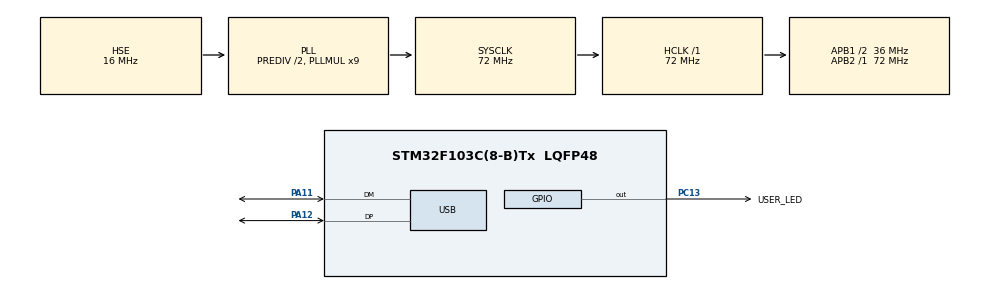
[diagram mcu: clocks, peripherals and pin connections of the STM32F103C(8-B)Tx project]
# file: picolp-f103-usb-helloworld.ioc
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Mcu.Family=STM32F1
Mcu.Name=STM32F103C(8-B)Tx
Mcu.Package=LQFP48
NVIC.PriorityGroup=NVIC_PRIORITYGROUP_4
NVIC.TIM1_CC_IRQn=true\:0\:0\:false\:false\:true\:true\:true\:true
NVIC.TIM1_UP_IRQn=true\:0\:0\:false\:false\:true\:true\:true\:true
NVIC.USB_LP_CAN1_RX0_IRQn=true\:0\:0\:false\:false\:true\:false\:true\:true
PA11.Mode=Device
PA11.Signal=USB_DM
PA12.Mode=Device
PA12.Signal=USB_DP
PA13.Mode=Serial_Wire
PA13.Signal=SYS_JTMS-SWDIO
PA14.Mode=Serial_Wire
PA14.Signal=SYS_JTCK-SWCLK
PC13-TAMPER-RTC.GPIO_Label=USER_LED
PC13-TAMPER-RTC.Signal=GPIO_Output
PD0-OSC_IN.Mode=HSE-External-Oscillator
PD0-OSC_IN.Signal=RCC_OSC_IN
PD1-OSC_OUT.Mode=HSE-External-Oscillator
PD1-OSC_OUT.Signal=RCC_OSC_OUT
ProjectManager.HeapSize=0x200
ProjectManager.StackSize=0x400
ProjectManager.TargetToolchain=STM32CubeIDE
RCC.AHBFreq_Value=72000000
RCC.APB1CLKDivider=RCC_HCLK_DIV2
RCC.APB1Freq_Value=36000000
RCC.APB1TimFreq_Value=72000000
RCC.APB2Freq_Value=72000000
RCC.APB2TimFreq_Value=72000000
RCC.HCLKFreq_Value=72000000
RCC.HSEDivPLL=RCC_HSE_PREDIV_DIV2
RCC.HSE_VALUE=16000000
RCC.PLLMUL=RCC_PLL_MUL9
RCC.SYSCLKFreq_VALUE=72000000
RCC.SYSCLKSource=RCC_SYSCLKSOURCE_PLLCLK
RCC.USBFreq_Value=48000000
RCC.USBPrescaler=RCC_USBCLKSOURCE_PLL_DIV1_5
TIM1.Channel-Output\ Compare1\ No\ Output=TIM_CHANNEL_1
TIM1.Period=10000-1
TIM1.Prescaler=7200-1
TIM1.Pulse-Output\ Compare1\ No\ Output=2000
TIM1.TIM_MasterOutputTrigger=TIM_TRGO_RESET
USB_DEVICE.CLASS_NAME_FS=CDC
USB_DEVICE.VirtualMode=Cdc
USB_DEVICE.VirtualModeFS=Cdc_FS
VP_TIM1_VS_ClockSourceINT.Mode=Internal
VP_TIM1_VS_no_output1.Mode=Output Compare1 No Output
VP_USB_DEVICE_VS_USB_DEVICE_CDC_FS.Mode=CDC_FS
board=custom

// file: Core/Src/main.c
/* USER CODE BEGIN Header */
/**
  ******************************************************************************
  * @file           : main.c
  * @brief          : Main program body
  ******************************************************************************
  * @attention
  *
  * Copyright (c) 2025 STMicroelectronics.
  * All rights reserved.
  *
  * This software is licensed under terms that can be found in the LICENSE file
  * in the root directory of this software component.
  * If no LICENSE file comes with this software, it is provided AS-IS.
  *
  ******************************************************************************
  */
/* USER CODE END Header */
#include "main.h"
#include "usb_device.h"

/* USER CODE BEGIN Includes */

#include "usbd_cdc_if.h"

/* USER CODE END Includes */

TIM_HandleTypeDef htim1;

void SystemClock_Config(void);
static void MX_GPIO_Init(void);
static void MX_TIM1_Init(void);

int main(void)
{

  /* MCU Configuration--------------------------------------------------------*/

  /* Reset of all peripherals, Initializes the Flash interface and the Systick. */
  HAL_Init();

  /* Configure the system clock */
  SystemClock_Config();

  /* Initialize all configured peripherals */
  MX_GPIO_Init();
  MX_TIM1_Init();
  MX_USB_DEVICE_Init();
  /* USER CODE BEGIN 2 */

  HAL_TIM_Base_Start_IT(&htim1);
  HAL_TIM_OC_Start_IT(&htim1, TIM_CHANNEL_1);

  /* USER CODE END 2 */

  /* Infinite loop */
  while (1)
  {

  }
}

void SystemClock_Config(void)
{
  RCC_OscInitTypeDef RCC_OscInitStruct = {0};
  RCC_ClkInitTypeDef RCC_ClkInitStruct = {0};
  RCC_PeriphCLKInitTypeDef PeriphClkInit = {0};

  /** Initializes the RCC Oscillators according to the specified parameters
  * in the RCC_OscInitTypeDef structure.
  */
  RCC_OscInitStruct.OscillatorType = RCC_OSCILLATORTYPE_HSE;
  RCC_OscInitStruct.HSEState = RCC_HSE_ON;
  RCC_OscInitStruct.HSEPredivValue = RCC_HSE_PREDIV_DIV2;
  RCC_OscInitStruct.HSIState = RCC_HSI_ON;
  RCC_OscInitStruct.PLL.PLLState = RCC_PLL_ON;
  RCC_OscInitStruct.PLL.PLLSource = RCC_PLLSOURCE_HSE;
  RCC_OscInitStruct.PLL.PLLMUL = RCC_PLL_MUL9;
  if (HAL_RCC_OscConfig(&RCC_OscInitStruct) != HAL_OK)
  {
    Error_Handler();
  }

  /** Initializes the CPU, AHB and APB buses clocks
  */
  RCC_ClkInitStruct.ClockType = RCC_CLOCKTYPE_HCLK|RCC_CLOCKTYPE_SYSCLK
                              |RCC_CLOCKTYPE_PCLK1|RCC_CLOCKTYPE_PCLK2;
  RCC_ClkInitStruct.SYSCLKSource = RCC_SYSCLKSOURCE_PLLCLK;
  RCC_ClkInitStruct.AHBCLKDivider = RCC_SYSCLK_DIV1;
  RCC_ClkInitStruct.APB1CLKDivider = RCC_HCLK_DIV2;
  RCC_ClkInitStruct.APB2CLKDivider = RCC_HCLK_DIV1;

  if (HAL_RCC_ClockConfig(&RCC_ClkInitStruct, FLASH_LATENCY_2) != HAL_OK)
  {
    Error_Handler();
  }
  PeriphClkInit.PeriphClockSelection = RCC_PERIPHCLK_USB;
  PeriphClkInit.UsbClockSelection = RCC_USBCLKSOURCE_PLL_DIV1_5;
  if (HAL_RCCEx_PeriphCLKConfig(&PeriphClkInit) != HAL_OK)
  {
    Error_Handler();
  }
}

static void MX_TIM1_Init(void)
{

  TIM_ClockConfigTypeDef sClockSourceConfig = {0};
  TIM_MasterConfigTypeDef sMasterConfig = {0};
  TIM_OC_InitTypeDef sConfigOC = {0};
  TIM_BreakDeadTimeConfigTypeDef sBreakDeadTimeConfig = {0};

  htim1.Instance = TIM1;
  htim1.Init.Prescaler = 7200-1;
  htim1.Init.CounterMode = TIM_COUNTERMODE_UP;
  htim1.Init.Period = 10000-1;
  htim1.Init.ClockDivision = TIM_CLOCKDIVISION_DIV1;
  htim1.Init.RepetitionCounter = 0;
  htim1.Init.AutoReloadPreload = TIM_AUTORELOAD_PRELOAD_DISABLE;
  if (HAL_TIM_Base_Init(&htim1) != HAL_OK)
  {
    Error_Handler();
  }
  sClockSourceConfig.ClockSource = TIM_CLOCKSOURCE_INTERNAL;
  if (HAL_TIM_ConfigClockSource(&htim1, &sClockSourceConfig) != HAL_OK)
  {
    Error_Handler();
  }
  if (HAL_TIM_OC_Init(&htim1) != HAL_OK)
  {
    Error_Handler();
  }
  sMasterConfig.MasterOutputTrigger = TIM_TRGO_RESET;
  sMasterConfig.MasterSlaveMode = TIM_MASTERSLAVEMODE_DISABLE;
  if (HAL_TIMEx_MasterConfigSynchronization(&htim1, &sMasterConfig) != HAL_OK)
  {
    Error_Handler();
  }
  sConfigOC.OCMode = TIM_OCMODE_TIMING;
  sConfigOC.Pulse = 2000;
  sConfigOC.OCPolarity = TIM_OCPOLARITY_HIGH;
  sConfigOC.OCNPolarity = TIM_OCNPOLARITY_HIGH;
  sConfigOC.OCFastMode = TIM_OCFAST_DISABLE;
  sConfigOC.OCIdleState = TIM_OCIDLESTATE_RESET;
  sConfigOC.OCNIdleState = TIM_OCNIDLESTATE_RESET;
  if (HAL_TIM_OC_ConfigChannel(&htim1, &sConfigOC, TIM_CHANNEL_1) != HAL_OK)
  {
    Error_Handler();
  }
  sBreakDeadTimeConfig.OffStateRunMode = TIM_OSSR_DISABLE;
  sBreakDeadTimeConfig.OffStateIDLEMode = TIM_OSSI_DISABLE;
  sBreakDeadTimeConfig.LockLevel = TIM_LOCKLEVEL_OFF;
  sBreakDeadTimeConfig.DeadTime = 0;
  sBreakDeadTimeConfig.BreakState = TIM_BREAK_DISABLE;
  sBreakDeadTimeConfig.BreakPolarity = TIM_BREAKPOLARITY_HIGH;
  sBreakDeadTimeConfig.AutomaticOutput = TIM_AUTOMATICOUTPUT_DISABLE;
  if (HAL_TIMEx_ConfigBreakDeadTime(&htim1, &sBreakDeadTimeConfig) != HAL_OK)
  {
    Error_Handler();
  }

}

static void MX_GPIO_Init(void)
{
  GPIO_InitTypeDef GPIO_InitStruct = {0};

  /* GPIO Ports Clock Enable */
  __HAL_RCC_GPIOC_CLK_ENABLE();
  __HAL_RCC_GPIOD_CLK_ENABLE();
  __HAL_RCC_GPIOA_CLK_ENABLE();

  /*Configure GPIO pin Output Level */
  HAL_GPIO_WritePin(USER_LED_GPIO_Port, USER_LED_Pin, GPIO_PIN_RESET);

  /*Configure GPIO pin : USER_LED_Pin */
  GPIO_InitStruct.Pin = USER_LED_Pin;
  GPIO_InitStruct.Mode = GPIO_MODE_OUTPUT_PP;
  GPIO_InitStruct.Pull = GPIO_NOPULL;
  GPIO_InitStruct.Speed = GPIO_SPEED_FREQ_LOW;
  HAL_GPIO_Init(USER_LED_GPIO_Port, &GPIO_InitStruct);

}

/* USER CODE BEGIN 4 */

void HAL_TIM_PeriodElapsedCallback(TIM_HandleTypeDef *htim) {
	const char tx_data[] = "Hello world!\r\n";
	if(CDC_Transmit_FS(tx_data, sizeof(tx_data)) == USBD_OK) {
		HAL_GPIO_WritePin(USER_LED_GPIO_Port, USER_LED_Pin, GPIO_PIN_SET);
	}
}

void HAL_TIM_OC_DelayElapsedCallback(TIM_HandleTypeDef *htim) {
	HAL_GPIO_WritePin(USER_LED_GPIO_Port, USER_LED_Pin, GPIO_PIN_RESET);
}

/* USER CODE END 4 */

void Error_Handler(void)
{
  __disable_irq();
  while (1)
  {
  }
}
